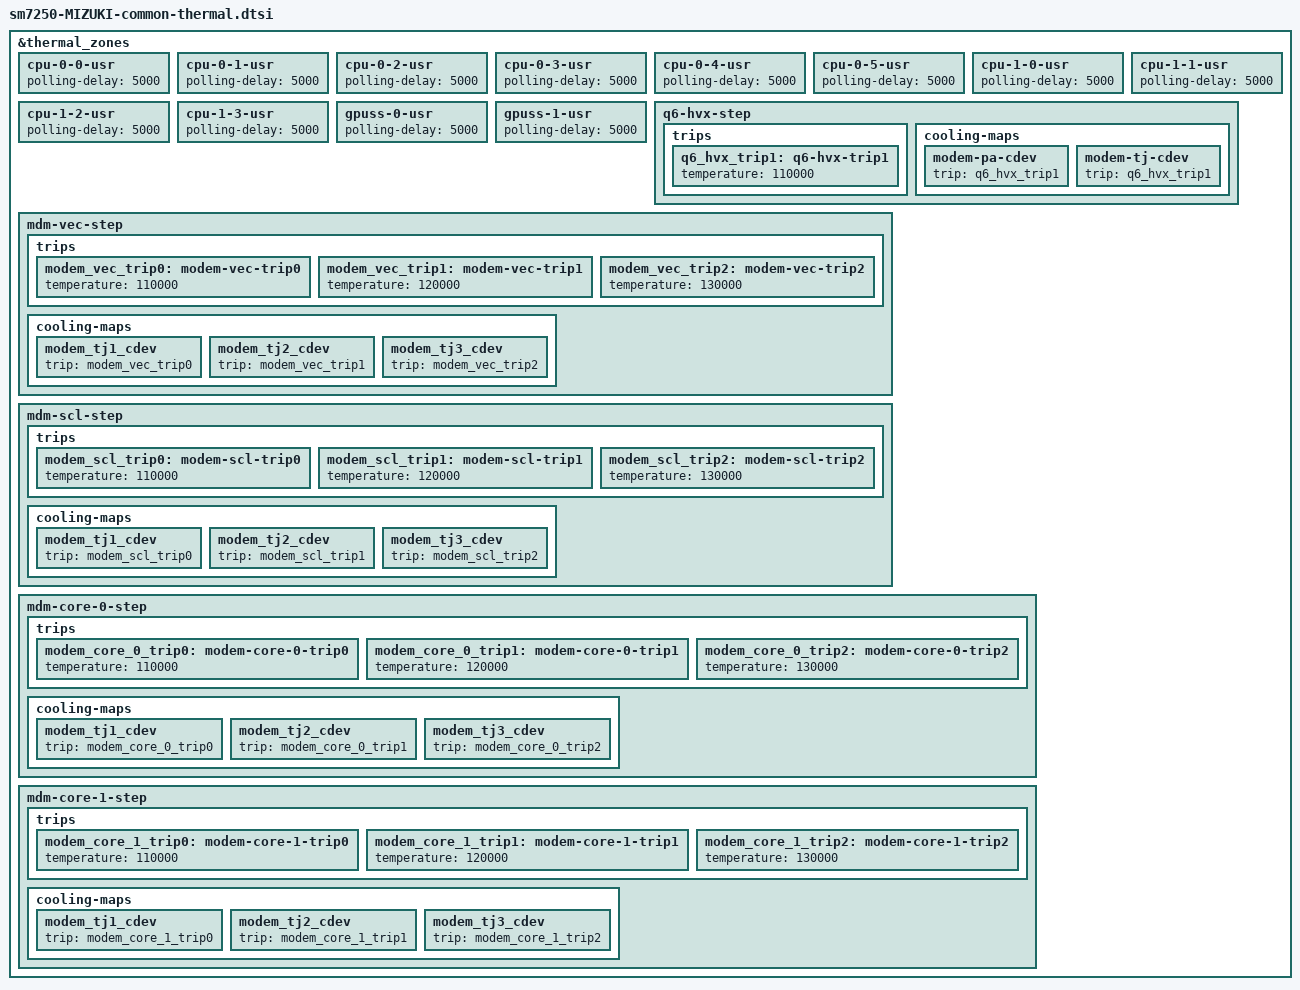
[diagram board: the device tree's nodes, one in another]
/*
 * This software is contributed or developed by KYOCERA Corporation.
 * (C) 2020 KYOCERA Corporation
 */

&thermal_zones {
	cpu-0-0-usr {
		polling-delay = <5000>;
	};

	cpu-0-1-usr {
		polling-delay = <5000>;
	};

	cpu-0-2-usr {
		polling-delay = <5000>;
	};

	cpu-0-3-usr {
		polling-delay = <5000>;
	};

	cpu-0-4-usr {
		polling-delay = <5000>;
	};

	cpu-0-5-usr {
		polling-delay = <5000>;
	};

	cpu-1-0-usr {
		polling-delay = <5000>;
	};

	cpu-1-1-usr {
		polling-delay = <5000>;
	};

	cpu-1-2-usr {
		polling-delay = <5000>;
	};

	cpu-1-3-usr {
		polling-delay = <5000>;
	};

	gpuss-0-usr {
		polling-delay = <5000>;
	};

	gpuss-1-usr {
		polling-delay = <5000>;
	};

	q6-hvx-step {
		trips {
			q6_hvx_trip1: q6-hvx-trip1 {
				temperature = <110000>;
			};
		};
		cooling-maps {
			modem-pa-cdev {
				trip = <&q6_hvx_trip1>;
			};

			modem-tj-cdev {
				trip = <&q6_hvx_trip1>;
			};
		};
	};

	mdm-vec-step {
		trips {
			modem_vec_trip0: modem-vec-trip0 {
				temperature = <110000>;
			};

			modem_vec_trip1: modem-vec-trip1 {
				temperature = <120000>;
			};

			modem_vec_trip2: modem-vec-trip2 {
				temperature = <130000>;
			};
		};

		cooling-maps {
			modem_tj1_cdev {
				trip = <&modem_vec_trip0>;
			};

			modem_tj2_cdev {
				trip = <&modem_vec_trip1>;
			};

			modem_tj3_cdev {
				trip = <&modem_vec_trip2>;
			};
		};
	};

	mdm-scl-step {
		trips {
			modem_scl_trip0: modem-scl-trip0 {
				temperature = <110000>;
			};

			modem_scl_trip1: modem-scl-trip1 {
				temperature = <120000>;
			};

			modem_scl_trip2: modem-scl-trip2 {
				temperature = <130000>;
			};
		};

		cooling-maps {
			modem_tj1_cdev {
				trip = <&modem_scl_trip0>;
			};

			modem_tj2_cdev {
				trip = <&modem_scl_trip1>;
			};

			modem_tj3_cdev {
				trip = <&modem_scl_trip2>;
			};
		};
	};

	mdm-core-0-step {
		trips {
			modem_core_0_trip0: modem-core-0-trip0 {
				temperature = <110000>;
			};

			modem_core_0_trip1: modem-core-0-trip1 {
				temperature = <120000>;
			};

			modem_core_0_trip2: modem-core-0-trip2 {
				temperature = <130000>;
			};
		};

		cooling-maps {
			modem_tj1_cdev {
				trip = <&modem_core_0_trip0>;
			};

			modem_tj2_cdev {
				trip = <&modem_core_0_trip1>;
			};

			modem_tj3_cdev {
				trip = <&modem_core_0_trip2>;
			};
		};
	};

	mdm-core-1-step {
		trips {
			modem_core_1_trip0: modem-core-1-trip0 {
				temperature = <110000>;
			};

			modem_core_1_trip1: modem-core-1-trip1 {
				temperature = <120000>;
			};

			modem_core_1_trip2: modem-core-1-trip2 {
				temperature = <130000>;
			};
		};

		cooling-maps {
			modem_tj1_cdev {
				trip = <&modem_core_1_trip0>;
			};

			modem_tj2_cdev {
				trip = <&modem_core_1_trip1>;
			};

			modem_tj3_cdev {
				trip = <&modem_core_1_trip2>;
			};
		};
	};
};
